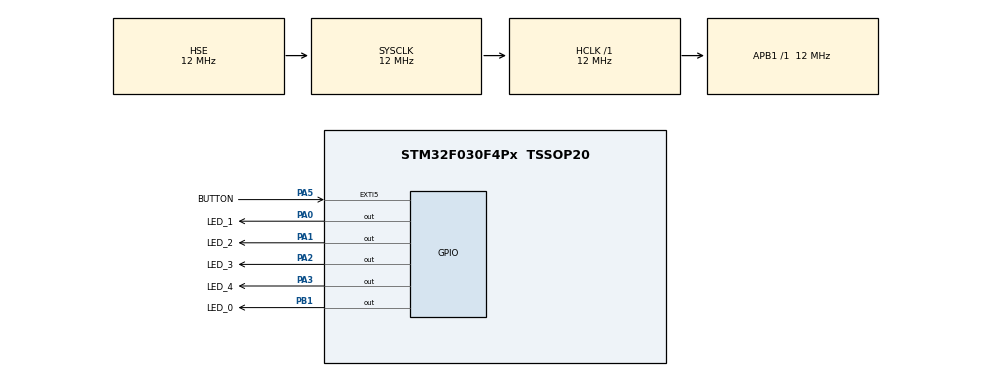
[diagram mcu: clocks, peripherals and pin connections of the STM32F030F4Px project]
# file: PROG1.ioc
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Mcu.Family=STM32F0
Mcu.Name=STM32F030F4Px
Mcu.Package=TSSOP20
NVIC.EXTI4_15_IRQn=true\:0\:0\:false\:false\:true\:true\:true\:true
PA0.GPIO_Label=LED_1
PA0.Signal=GPIO_Output
PA1.GPIO_Label=LED_2
PA1.Signal=GPIO_Output
PA13.Mode=Serial_Wire
PA13.Signal=SYS_SWDIO
PA14.Mode=Serial_Wire
PA14.Signal=SYS_SWCLK
PA2.GPIO_Label=LED_3
PA2.Signal=GPIO_Output
PA3.GPIO_Label=LED_4
PA3.Signal=GPIO_Output
PA5.GPIO_Label=BUTTON
PA5.Signal=GPXTI5
PB1.GPIO_Label=LED_0
PB1.Signal=GPIO_Output
PF0-OSC_IN.Mode=HSE-External-Oscillator
PF0-OSC_IN.Signal=RCC_OSC_IN
PF1-OSC_OUT.Mode=HSE-External-Oscillator
PF1-OSC_OUT.Signal=RCC_OSC_OUT
ProjectManager.HeapSize=0x200
ProjectManager.StackSize=0x400
ProjectManager.TargetToolchain=STM32CubeIDE
RCC.AHBFreq_Value=12000000
RCC.APB1Freq_Value=12000000
RCC.APB1TimFreq_Value=12000000
RCC.HCLKFreq_Value=12000000
RCC.HSE_VALUE=12000000
RCC.SYSCLKFreq_VALUE=12000000
RCC.SYSCLKSource=RCC_SYSCLKSOURCE_HSE
board=custom

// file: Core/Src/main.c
/* USER CODE BEGIN Header */
/**
  ******************************************************************************
  * @file           : main.c
  * @brief          : Main program body
  ******************************************************************************
  * @attention
  *
  * Copyright (c) 2024 STMicroelectronics.
  * All rights reserved.
  *
  * This software is licensed under terms that can be found in the LICENSE file
  * in the root directory of this software component.
  * If no LICENSE file comes with this software, it is provided AS-IS.
  *
  ******************************************************************************
  */
/* USER CODE END Header */
#include "main.h"
#include "gpio.h"

/* USER CODE BEGIN Includes */
#include "button.h"
/* USER CODE END Includes */

void SystemClock_Config(void);

int main(void)
{

  /* MCU Configuration--------------------------------------------------------*/

  /* Reset of all peripherals, Initializes the Flash interface and the Systick. */
  HAL_Init();

  /* Configure the system clock */
  SystemClock_Config();

  /* Initialize all configured peripherals */
  MX_GPIO_Init();
  /* USER CODE BEGIN 2 */
  button_init();
  /* USER CODE END 2 */

  /* Infinite loop */
  while (1)
  {
	  if (PRESSED == button_get_state())
	  {
		  HAL_GPIO_TogglePin(GPIOB, LED_0);
	  }
  }
}

void SystemClock_Config(void)
{
  RCC_OscInitTypeDef RCC_OscInitStruct = {0};
  RCC_ClkInitTypeDef RCC_ClkInitStruct = {0};

  /** Initializes the RCC Oscillators according to the specified parameters
  * in the RCC_OscInitTypeDef structure.
  */
  RCC_OscInitStruct.OscillatorType = RCC_OSCILLATORTYPE_HSE;
  RCC_OscInitStruct.HSEState = RCC_HSE_ON;
  RCC_OscInitStruct.PLL.PLLState = RCC_PLL_NONE;
  if (HAL_RCC_OscConfig(&RCC_OscInitStruct) != HAL_OK)
  {
    Error_Handler();
  }

  /** Initializes the CPU, AHB and APB buses clocks
  */
  RCC_ClkInitStruct.ClockType = RCC_CLOCKTYPE_HCLK|RCC_CLOCKTYPE_SYSCLK
                              |RCC_CLOCKTYPE_PCLK1;
  RCC_ClkInitStruct.SYSCLKSource = RCC_SYSCLKSOURCE_HSE;
  RCC_ClkInitStruct.AHBCLKDivider = RCC_SYSCLK_DIV1;
  RCC_ClkInitStruct.APB1CLKDivider = RCC_HCLK_DIV1;

  if (HAL_RCC_ClockConfig(&RCC_ClkInitStruct, FLASH_LATENCY_0) != HAL_OK)
  {
    Error_Handler();
  }
}

void Error_Handler(void)
{
  __disable_irq();
  while (1)
  {
  }
}
